# pdm_secure register map
Vendor: Texas Instruments
Peripheral module from a debugger description file (folder CC35X1E).
Registers are 32-bit, read-only, reset 0x0 unless marked. A register's access mark holds for its fields unless they carry their own. Offsets are as the file gives them; lines under a group give offsets from that group; [hi:lo] are bit positions; {n}, {i} and the like mark numbered series; 'fields as' and 'values as' point back to an identical list; <NAME> marks a mode.

## pdm_secure
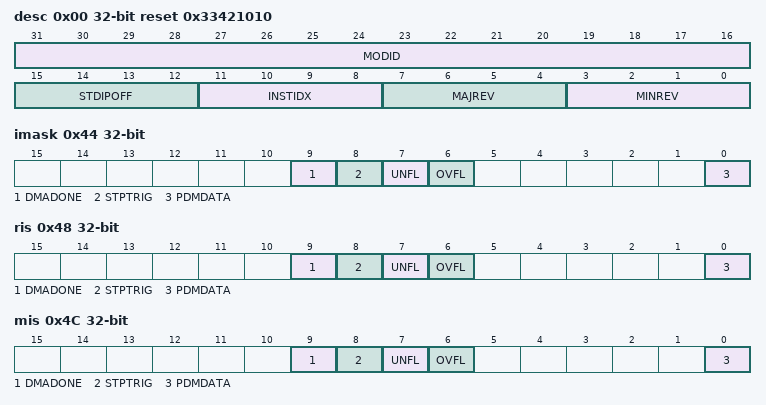
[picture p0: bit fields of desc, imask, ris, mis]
0x00 desc reset 0x33421010 — Description Register This register identifies the peripheral and its exact version.
  [31:16] MODID — Module identification contains a unique peripheral identification number. The assignments are maintained in a central database for all of the platform modules to ensure uniqueness.
    0=MINIMUM (Smallest value); 0xFFFF=MAXIMUM (Highest possible value)
  [15:12] STDIPOFF — Standard IP offset 64 Bit standard IP MMR block (beginning with aggregated IRQ registers) 0: STDIP MMRs do not exist 1:15: These MMRs begin at offset 64*STDIPOFF from IP base address
    0=MINIMUM (Smallest value); 15=MAXIMUM (Highest possible value)
  [11:8] INSTIDX — Instance Number within the device. This will be a parameter to the RTL for modules that can have multiple instances
    values as STDIPOFF
  [7:4] MAJREV — Major revision of the IP
    values as STDIPOFF
  [3:0] MINREV — Minor revision of the IP
    values as STDIPOFF
0x04 descex reset 0x4 — This register reflects the configuration of this peripheral instance
  [2:0] NUMCHAN — Number of available PDM Channels. Value 1 indicates two channels that can be used for stereo or dual mono microphone connections.
    0=MINIMUM (Smallest value); 7=MAXIMUM (Highest possible value)
0x44 imask access per field — Interrupt Mask. If a bit is set, then corresponding interrupt is un-masked. Un-masking the interrupt causes the raw interrupt to be visible in MIS.
  [9] DMADONE rw — DMA Done event mask.
    0=CLR (Interrupt disable); 1=SET (Interrrupt Enable)
  [8] STPTRIG rw — Samplestamp Trigger event mask
    1=SET (Interrrupt Enable); 0=CLR (Clear Interrupt Mask)
  [7] UNFL rw — Data Underflow event mask.
    0=CLR (Interrupt disable); 1=SET (Interrrupt Enable)
  [6] OVFL rw — Data Overflow event mask.
    0=CLR (Interrupt disable); 1=SET (Interrrupt Enable)
  [0] PDMDATA rw — *PDM* data event mask
    0=CLR (Interrupt disable); 1=SET (Interrupt Enable)
0x48 ris — Raw interrupt status. Reflects all pending interrupts, regardless of masking. The RIS register allows the user to implement a poll scheme. A flag set in this register can be cleared by writing 1 to the ICLR register bit even if the corresponding IMASK bit is not enabled.
  [9] DMADONE — DMA Done event.
    0=CLR (Interrupt disable); 1=SET (Interrrupt Enable)
  [8] STPTRIG — Samplestamp Trigger event
    1=SET (Interrrupt Enable); 0=CLR (Interrupt did not occur)
  [7] UNFL — Data Underflow event. Data has been read from an emty FIFO. This flag gets set if one of the channel UNDERFLOW flags gets set.
    0=CLR (Interrupt disable); 1=SET (Interrrupt Enable)
  [6] OVFL — Data Overflow event. Data has been written to the buffer before the previous values was read. This flag gets set if one of the channel OVERFLOW flags gets set
    0=CLR (Interrupt disable); 1=SET (Interrrupt Enable)
  [0] PDMDATA — PDM DATA event
    0=CLR (Interrupt disable); 1=SET (Interrrupt Enable)
0x4C mis — Masked interrupt status. This is an AND of the IMASK and RIS registers.
  [9] DMADONE — Masked DMA Done event.
    0=CLR (Interrupt disable); 1=SET (Interrrupt Enable)
  [8] STPTRIG — Masked Samplestamp Trigger event.
    1=SET (Interrrupt Enable); 0=CLR (Interrupt did not occur)
  [7] UNFL — Masked Data Underflow event.
    0=CLR (Interrupt disable); 1=SET (Interrrupt Enable)
  [6] OVFL — Masked Data Overflow event.
    0=CLR (Interrupt disable); 1=SET (Interrrupt Enable)
  [0] PDMDATA — Masked PDMDATA event
    0=CLR (Interrupt disable); 1=SET (Interrrupt Enable)
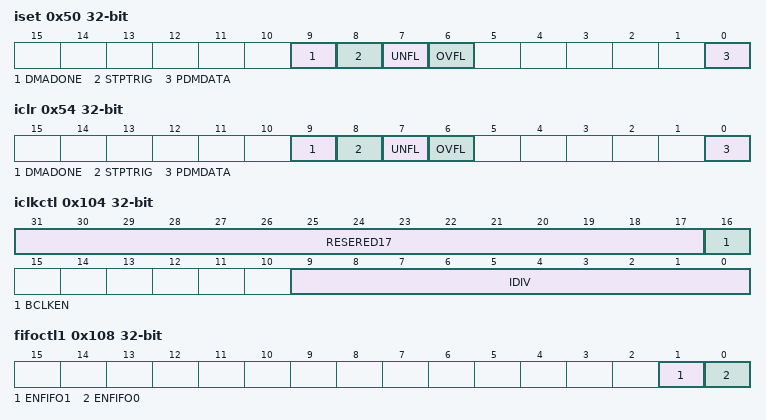
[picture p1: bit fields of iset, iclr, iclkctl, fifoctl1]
0x50 iset access per field — Interrupt set. Allows interrupts to be set by software (useful in diagnostics and safety checks). Writing a 1 to a bit in ISET will set the event and therefore the related RIS bit also gets set. If the interrupt is enabled through the mask, then the corresponding MIS bit is also set.
  [9] DMADONE wo — Set DMA Done event.
    0=NO_EFFECT (Interrupt disable); 1=SET (Interrrupt Enable)
  [8] STPTRIG wo — Set Samplestamp Trigger event.
    1=SET (Interrrupt Enable); 0=NO_EFFECT (Writing 0 has no effect)
  [7] UNFL wo — Set Data Underflow event.
    0=NO_EFFECT (Interrupt disable); 1=SET (Interrrupt Enable)
  [6] OVFL wo — Set Data Overflow event.
    0=NO_EFFECT (Interrupt disable); 1=SET (Interrrupt Enable)
  [0] PDMDATA wo — Set PDMDATA event.
    0=NO_EFFECT (Interrupt disable); 1=SET (Interrrupt Enable)
0x54 iclr access per field — Interrupt clear. Write a 1 to clear corresponding Interrupt.
  [9] DMADONE wo — Clear DMA Done event.
    0=NO_EFFECT (Interrupt disable); 1=CLR (Interrrupt Enable)
  [8] STPTRIG wo — Clear Samplestamp Trigger event.
    1=CLR (Interrrupt Enable); 0=NO_EFFECT (Writing 0 has no effect)
  [7] UNFL wo — Clear Data Underflow event.
    0=NO_EFFECT (Interrupt disable); 1=CLR (Interrrupt Enable)
  [6] OVFL wo — Clear Data Overflow event.
    0=NO_EFFECT (Interrupt disable); 1=CLR (Interrrupt Enable)
  [0] PDMDATA wo — Clear PDMDATA event.
    0=NO_EFFECT (Interrupt disable); 1=CLR (Interrrupt Enable)
0x60 emu access per field — This register can be used by the software developer to control the behavior of the peripheral relative to the 'Core Halted' input
  [0] HALT rw — Free run control
    1=STOP (The peripheral freezes functionality while the Core Halted input is asserted and resumes when it is deasserted.); 0=RUN (The peripheral ignores the state of the Core Halted input)
0x100 ctl access per field — PDM control register
  [0] ENPDM rw — Enable conversion on *PDM*
    0=DIS (Disable Channel); 1=EN (Enable Channel)
0x104 iclkctl access per field — Input clock Control Register
  [31:17] RESERED17 ro — Software should not rely on the value of a reserved. Writing any other value than the reset value may result in undefined behavior.
  [16] BCLKEN rw — This bit is used to enable BCLK to Sigma-Delta Modulator on-chip.
    0=DIS (BCLK is disabled); 1=EN (BCLK is enabled)
  [9:0] IDIV rw — Divider for ICLK iclk = PLLCLK/(ICLK +1)
    0=MIN (Minimum value of BDIV); 0x3FF=MAX (Maximum value of BDIV)
0x108 fifoctl1 access per field — PDM FIFO control register
  [1] ENFIFO1 rw — Enable FIFO1 for DMA access through the [FIFODATA] Register
    0=DIS (Disable Channel); 1=EN (Enable Channel)
  [0] ENFIFO0 rw — Enable FIFO0 for DMA access through the [FIFODATA] Register
    0=DIS (Disable Channel); 1=EN (Enable Channel)
0x10C fifodata — *FIFO* Data Register (FIFO read) This register provides the Data of the FIFO based on [FIFOCTL.ENFIFO0] and [FIFOCTL.ENFIFO1] This allows the DMA to just have single address to read all the FIFO content when triggered.
  [31:0] VALUE — FIFO Read Register
    0=MINIMUM (Smallest value); 0xFFFFFFFF=MAXIMUM (Highest possible value)
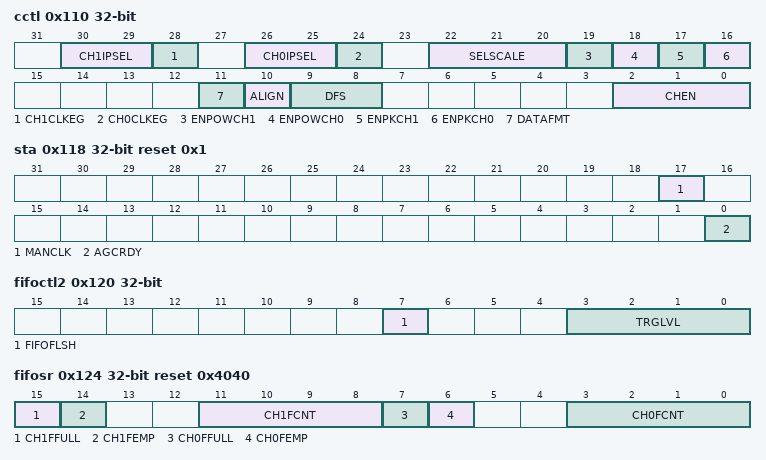
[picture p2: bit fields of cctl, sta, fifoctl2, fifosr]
0x110 cctl access per field reset not defined — PDM Channel control register
  [30:29] CH1IPSEL rw — Channel 1 Data Input Select
    0=DATA0 (Data pin 0 selected as source for channel 1.); 1=DATA1 (Data pin 1 selected as source for channel 1.); 2=SDM (SDM output selected as source for channel 1.); 3=Reserved (Data pin 0 selected as source for channel 1.)
  [28] CH1CLKEG rw — Select the clock edge for data channel 1
    0=RISING (Rising edge is selected); 1=FALLING (Failing edge is selected)
  [26:25] CH0IPSEL rw — Channel 0 Data Input Select
    0=DATA0 (Data pin 0 selected as source for channel 0.); 1=DATA1 (Data pin 1 selected as source for channel 0.); 2=SDM (SDM output selected as source for channel 0.); 3=Reserved (Data pin 0 selected as source for channel 0.)
  [24] CH0CLKEG rw — Select the clock edge for data channel 0
    values as CH1CLKEG
  [22:20] SELSCALE rw — Select scaling factor for the averaging blocks. Selscale value used internally is 1/(2^(3+VALUE)) Ex: When value is 0, selscale is 1/8, and when value is 7, selscale is 1/1024
    0=Scaling factor is 1/8; 1=Scaling factor is 1/16; 2=Scaling factor is 1/32; 3=Scaling factor is 1/64; 4=Scaling factor is 1/128; 5=Scaling factor is 1/256; 6=Scaling factor is 1/512; 7=Scaling factor is 1/1024
  [19] ENPOWCH1 rw — Enables average power calculation for channel-1
    1=EN (Enables average power calculation for channel-1); 0=DIS (Enables average power calculation for channel-1)
  [18] ENPOWCH0 rw — Enables average power calculation for channel-0
    1=EN (Enables average power calculation for channel-0); 0=DIS (Disables average power calculation for channel-0)
  [17] ENPKCH1 rw — Enables peak value detection for channel-0
    1=EN (Enables peak value detection for channel-1); 0=DIS (Enables peak value detection for channel-1)
  [16] ENPKCH0 rw — Enables peak value detection for channel-0
    1=EN (Enables peak value detection for channel-0); 0=DIS (Disables peak value detection for channel-0)
  [11] DATAFMT rw — Data Format
    0=OFFSET (Offset binary); 1=TWOSCOMP (Twos complement)
  [10] ALIGN rw — Data alignment
    0=RIGHT (Right-aligned. LSB of filter output is bit 0.); 1=LEFT (Left-aligned. MSB of filter output (depending on OSR) is bit 31.)
  [9:8] DFS rw — Digital Filter Select
    {v}=SINC{v+1} (SINC{v+1} filter) (v=0..3)
  [2:0] CHEN rw — Data Input Configuration
    1=CH0ENABLE (Input channel 0 is enabled.); 2=CH0_1ENABLE (Input channel 1 is enabled.); 4=MANC (Input from Manchester Decoder, also enables Manchester Coding of bitstream. CH0 is enabled by default as the operation and CH1 enable bit is discarded.); 0=DISABLE (Both Channels are disabled.)
0x114 osr access per field reset 0x3F3F — Oversampling Control Register
  [7:0] VALUE rw — Oversampling rate. The oversampling rate is defined as OSRx + 1. Applicable oversampling rates are 2 to 256. Default is 64.
    1=MINIMUM (Smallest value); 255=MAXIMUM (Highest possible value)
0x118 sta reset 0x1 — PDM control register
  [17] MANCLK — Manchester Clock status. Indicates that Manchester mode is in locked mode or not.
    0=UNLOCKED (Manchester clock not locked.); 1=LOCKED (Manchester clock locked.)
  [0] AGCRDY — *AGC* accelerator ready status. Software must read AGCVALx, PKVALx and AVGPOWx registers only when AGCRDY is '1'. Reading these registers while AGCRDY is 0 may provide incorrect values.
    0=NOT_RDY (Not ready); 1=RDY (Ready)
0x120 fifoctl2 access per field — FIFO Control
  [7] FIFOFLSH rw — FIFO Flush Setting this bit will Flush the FIFO. This bit will self-clear when the flush has completed.
    0=NOFLUSH (Do not Flush FIFO); 1=FLUSH (Flush FIFO)
  [3:0] TRGLVL rw — FIFO Trigger Level Select Sets the trigger points for the FIFO events. Note: FIFO depth is only 2 the level 1/4 and 3/4 default to 1/2.
    {v}=LEVEL_{v+1} (Trigger when RX FIFO contains >= {v+1} byte) (v=0..11)
0x124 fifosr reset 0x4040 — FIFO Status Register.
  [15] CH1FFULL — CH1 FIFO Full
    0=CLEARED (The transmitter is not full.); 1=SET (If the FIFO is disabled (FEN is 0), the transmit holding register is full. If the FIFO is enabled (FEN is 1), the transmit FIFO is full.)
  [14] CH1FEMP — CH1 FIFO Empty
    0=CLEARED (The transmitter has data to transmit.); 1=SET (If the FIFO is disabled (FEN is 0), the transmit holding register is empty. If the FIFO is enabled (FEN is 1), the transmit FIFO is empty.)
  [11:8] CH1FCNT — Number of Bytes which could be read from the CH1 FIFO
    values as desc.STDIPOFF
  [7] CH0FFULL — CH0 FIFO Full
    0=CLEARED (The receiver can receive data.); 1=SET (If the FIFO is disabled (FEN is 0), the receive holding register is full. If the FIFO is enabled (FEN is 1), the receive FIFO is full.)
  [6] CH0FEMP — CH0 FIFO Empty
    0=CLEARED (The receiver is not empty.); 1=SET (If the FIFO is disabled (FEN is 0), the receive holding register is empty. If the FIFO is enabled (FEN is 1), the receive FIFO is empty.)
  [3:0] CH0FCNT — Number of Bytes which could be read from the CH0 FIFO
    values as desc.STDIPOFF
0x200 avgval0 — Average sample value for channel-0, 32-bit register.
  [31:0] VALUE — Average sample value for channel-0
    0=MINIMUM (Minimum value of register); 0xFFFFFFFF=MAXIMUM (Highest value)
0x204 pkval0 — Peak sample value for channel-0
  [23:0] VALUE — Peak sample value for channel-0. Bits [22:0] applicable for operation in 2's complement format and bits [23:0] applicable for operation in offset binary format.
    0=MINIMUM (Smallest value); 0x7FFFFF=MAXIMUM (Largest value)
0x208 avgpow0 — Average sample power for channel-0
  [31:0] VALUE
    0=MINIMUM (Smallest value); 0xFFFFFFFF=MAXIMUM (Highest value)
0x20C avgval1 — Average sample value for channel-1, 32-bit register.
  [31:0] VALUE — Average sample value for channel-1
    values as avgval0.VALUE
0x210 pkval1 — Peak sample value for channel-1
  [23:0] VALUE — Peak sample value for channel-1. Bits [22:0] applicable for operation in 2's complement format and bits [23:0] applicable for operation in offset binary format.
    0=MINIMUM (Smallest value); 0x7FFFFF=MAXIMUM (Largest value)
0x214 avgpow1 — Average sample power for channel-1
  fields as avgpow0
0x300 stpctl access per field — Samplestamp Generator Control Register
  [0] STPEN rw — Enables the samplestamp generator. The samplestamp generator must only be enabled after it has been properly configured.;When cleared, all samplestamp generator counters and capture values are cleared.
    0=DIS (Disable the samplestamp generator); 1=EN (Enable the samplestamp generator)
0x304 stpxcapt — Captured REFCLK Counter Value, Capture Channel 0
  [15:0] CAPTVAL — The value of the samplestamp XOSC counter [STMPXCNT.CURR_VALUE] last time an event was pulsed. The value is cleared when [STMPCTL.STMP_EN] = 0. Note: When calculating the fractional part of the sample stamp, [STMPXPER] may be less than this bit field.
    values as desc.MODID
0x308 stpxper — REFCLK Period Value
  [15:0] VALUE — The number of REFCLK clock cycles in the previous Sample Clock period (that is - the next value of the REFCLK counter at the positive Sample Clock edge, had it not been reset to 0).;The value is cleared when [STMPCTL.STMP_EN] = 0.
    values as desc.MODID
0x30C stpwcapt — Captured Sample Clock Counter Value, Capture Channel 0
  [15:0] CAPTVAL — The value of the samplestamp Sample Clock counter [STMPWCNT.CURR_VALUE] last time an event was pulsed. This number corresponds to the number of positive Sample Clock edges since the samplestamp generator was enabled;The value is cleared when [STMPCTL.STPEN] = 0.
    values as desc.MODID
0x310 stpwper access per field — Sample Clock Counter Period Value
  [15:0] VALUE rw — Used to define when [STMPWCNT] is to be reset so number of Sample Clock edges are found for the size of the sample buffer. This is thus a modulo value for the Sample Clock counter. This number must correspond to the size of the sample buffer used by the system (that is the index of the last sample plus 1).
    values as desc.MODID
0x314 stpintrg access per field — WS Counter Trigger Value for Input Pins
  [15:0] INSTRWCT rw — In Start W Count Compare value used to start the incoming audio streams.;This bit field must equal the Sample Clock counter value during the Sample Clock period in which the first input word(s) are sampled and stored to memory (that is the sample at the start of the very first DMA input buffer).;The value of this register takes effect when at least 32 PDMxCLK cycle ticks have happened.;Note: To avoid false triggers, this bit field must be set higher than [STPWPER.VALUE].
    values as desc.MODID
0x318 stpwset access per field — Sample Clock Counter Set Operation
  [15:0] VALUE rw — Sample Clock counter modification: Sets the running Sample Clock counter equal to the written value.
    values as desc.MODID
0x31C stpwadd access per field — Sample Clock Counter Add Operation
  [15:0] VALINC rw — Sample Clock counter modification: Adds the written value to the running Sample Clock counter. If a positive edge of Sample Clock occurs at the same time as the operation, this will be taken into account.;To add a negative value, write "[STMPWPER.VALUE] - value".;
    values as desc.MODID
0x320 stpxmin access per field reset 0xFFFF — REFCLK Minimum Period Value;Minimum Value of [STPXPER]
  [15:0] VALUE rw — Each time [STMPXPER] is updated, the value is also loaded into this register, provided that the value is smaller than the current value in this register.;When written, the register is reset to 0xFFFF (65535), regardless of the value written.;The minimum value can be used to detect extra Sample Clock pulses (this registers value will be significantly smaller than [STMPXPER.VALUE]).
    values as desc.MODID
0x324 stpwcnt — Current Value of sample clock count This register is reset when [STPCTL.STPEN] = 0.
  [15:0] CURRVAL — Current value of the Sample Clock counter
    values as desc.MODID
0x328 stpxcnt — Current Value of XCNT This register is reset when [STPCTL.STPEN] = 0.
  [15:0] CURRVAL — Current value of the REFCLK counter, latched when reading [STMPWCNT].
    values as desc.MODID
0x32C stpstat — Samplestamp Generator Status Register
  [1] INRDY — Low until the input pins are ready to be started by the samplestamp generator. When started (that is [STMPINTRIG] equals the WCLK counter) the bit goes back low.
    0=CLR (Clear); 1=SET
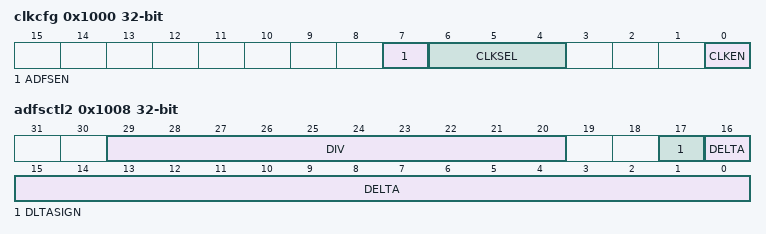
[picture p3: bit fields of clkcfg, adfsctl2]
0x1000 clkcfg access per field — Clock configuration register Note: Disable the [CLKCFG.MEM_CLK_EN] and [CLKCFG.ADFS_EN] to change [CLK_CFG.MEM_CLK_SEL] or [ADFS_CTRL1]/[ADFS_CTRL2] After changing [CLK_CFG.MEM_CLK_SEL] or [ADFS_CTRL1]/[ADFS_CTRL2], enable [CLKCFG.ADFS_EN] followed by [CLKCFG.MEM_CLK_EN]
  [7] ADFSEN rw — ADFS Enable bit
    0=DIS (Disable ADFS); 1=EN (Enable ADFS)
  [6:4] CLKSEL rw — Clock Select
    0=SEL_0 (No Clock); 1=SEL_1 (SOC Clock(80MHz)); 2=SEL_2 (SOC PLL Clock(un-swallowed 80MHz)); 3=SEL_3 (HFXT)
  [0] CLKEN rw — Clock enable
    0=DIS (Disable Clock); 1=EN (Enable Clock)
0x1004 adfsctl1 access per field — ADFS control register
  [20:0] TREF rw — Reference clock time period
0x1008 adfsctl2 access per field — ADFS control register 2
  [29:20] DIV rw — Value of divider to be used for ADFS
  [17] DLTASIGN rw — Sign of delta value to be used.
    0=POS (Positive Sign); 1=NEG (Negative sign)
  [16:0] DELTA rw — Difference in time periods of (reference clk/divisor) and required clock
